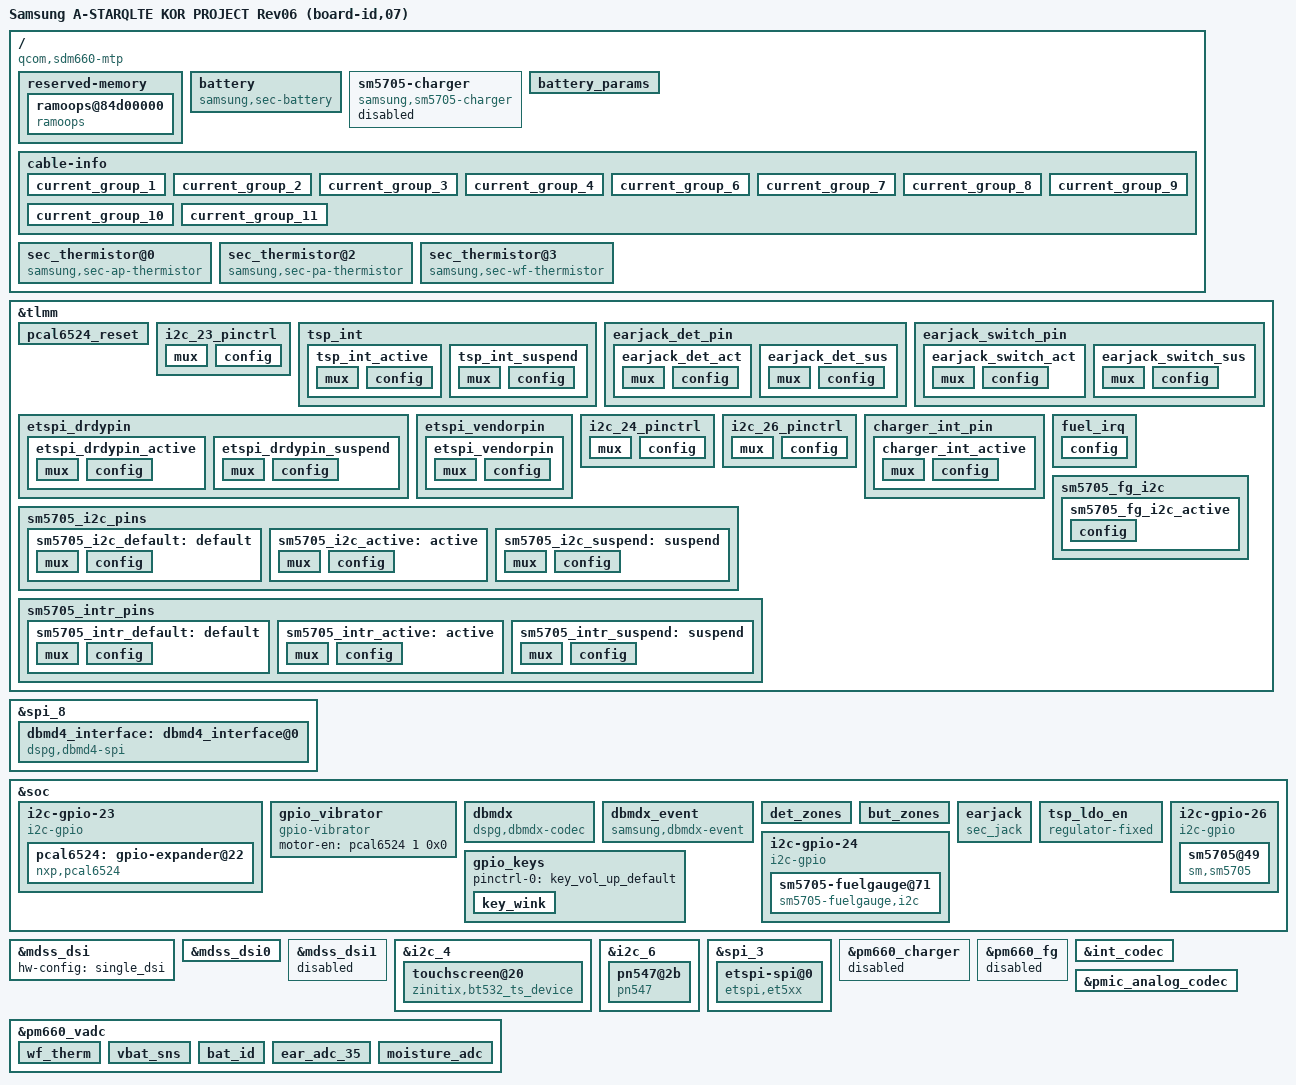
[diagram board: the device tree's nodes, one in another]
// SPDX-License-Identifier: GPL-2.0
/*
 * Samsung Galaxy A8 Star (SM-G885S, codename astarqlte, SoC SDM660).
 * Phase 1: boot essentials, volume/bixby keys, touch power and touch IC.
 */

/dts-v1/;

#include "sdm660.dtsi"
#include "sdm660-mtp.dtsi"
#include "sdm660-external-codec.dtsi"
#include "dsi-panel-s6e3fa7-ams628rf01-fhd-cmd.dtsi"
#include <dt-bindings/iio/qcom,spmi-vadc.h>

/ {
	model = "Samsung A-STARQLTE KOR PROJECT Rev06 (board-id,07)";
	compatible = "qcom,sdm660-mtp", "qcom,sdm660", "qcom,mtp";
	qcom,msm-id = <0x13d 0x0>;
	qcom,board-id = <0x8 0x7>;

	reserved-memory {
		/* base sdm660.dtsi ramoops (0x9ff00000) replaced by stock layout */
		/delete-node/ ramoops;

		ramoops@84d00000 {
			compatible = "ramoops";
			reg = <0x0 0x84d00000 0x0 0x100000>;
			record-size = <0x40000>;
			console-size = <0x40000>;
			ftrace-size = <0x40000>;
			pmsg-size = <0x40000>;
		};
	};
};

&tlmm {
	/*
	 * PCAL6524 expander reset line. Held high (out of reset) from boot,
	 * the same as the stock expander_reset_active pinctrl state.
	 */
	pcal6524_reset {
		gpio-hog;
		gpios = <33 0>;
		output-high;
		line-name = "pcal6524-reset";
	};

	i2c_23_pinctrl: i2c_23_pinctrl {
		mux {
			pins = "gpio52", "gpio51";
			function = "gpio";
		};

		config {
			pins = "gpio52", "gpio51";
			drive-strength = <2>;
			bias-disable;
		};
	};

	tsp_int {
		tsp_int_active: tsp_int_active {
			mux {
				pins = "gpio67";
				function = "gpio";
			};

			config {
				pins = "gpio67";
				drive-strength = <2>;
				bias-disable;
				input-enable;
			};
		};

		tsp_int_suspend: tsp_int_suspend {
			mux {
				pins = "gpio67";
				function = "gpio";
			};

			config {
				pins = "gpio67";
				drive-strength = <2>;
				bias-disable;
				input-enable;
			};
		};
	};
};

&tlmm {
	earjack_det_pin {
		earjack_det_act: earjack_det_act {
			mux {
				pins = "gpio43";
				function = "gpio";
			};

			config {
				pins = "gpio43";
				drive-strength = <2>;
				bias-disable;
			};
		};

		earjack_det_sus: earjack_det_sus {
			mux {
				pins = "gpio43";
				function = "gpio";
			};

			config {
				pins = "gpio43";
				drive-strength = <2>;
				bias-disable;
			};
		};
	};

	earjack_switch_pin {
		earjack_switch_act: earjack_switch_act {
			mux {
				pins = "gpio44";
				function = "gpio";
			};

			config {
				pins = "gpio44";
				drive-strength = <2>;
				bias-disable;
			};
		};

		earjack_switch_sus: earjack_switch_sus {
			mux {
				pins = "gpio44";
				function = "gpio";
			};

			config {
				pins = "gpio44";
				drive-strength = <2>;
				bias-disable;
			};
		};
	};
};

&spi_8 {
	status = "okay";

	dbmd4_interface: dbmd4_interface@0 {
		compatible = "dspg,dbmd4-spi";
		spi-max-frequency = <0xf4240>;
		read-chunk-size = <0x2000>;
		write-chunk-size = <0x40000>;
		reg = <0x0>;
		qcom,spiop-read = <0x3 0x3 0x0 0x0 0x0>;
		qcom,spiop-readseq = <0x3 0x3 0x0 0x0 0x0>;
		qcom,spiop-queryid = <0x90 0x3 0x0 0x0 0x0>;
		qcom,spiop-pprog = <0x2 0x2 0x0 0x0 0x0>;
		qcom,spiop-wenable = <0x6 0x0 0x0 0x0 0x0>;
		qcom,spiop-readst = <0x5 0x0 0x0 0x0 0x0>;
		qcom,spiop-erase = <0x20 0x2 0x0 0xa 0x1e>;
		qcom,spi-busy-mask = <0x1>;
		qcom,spi-page-size = <0x256>;
		qcom,spi-erase-size = <0x4096>;
	};
};

&soc {
	/*
	 * Stock i2c@23 (i2c-gpio, SDA = gpio52, SCL = gpio51). The PCAL6524
	 * expander and everything behind it hangs off this bus.
	 */
	i2c-gpio-23 {
		compatible = "i2c-gpio";
		gpios = <&tlmm 52 0 &tlmm 51 0>;
		i2c-gpio,delay-us = <2>;
		#address-cells = <1>;
		#size-cells = <0>;
		pinctrl-names = "default";
		pinctrl-0 = <&i2c_23_pinctrl>;

		pcal6524: gpio-expander@22 {
			compatible = "nxp,pcal6524";
			reg = <0x22>;
			gpio-controller;
			#gpio-cells = <2>;
		};
	};

	/* Motor enable is expander pin 1 (stock msm_vibrator motor-en). */
	gpio_vibrator {
		compatible = "gpio-vibrator";
		motor-en = <&pcal6524 1 0x0>;
	};

	/*
	 * dbmdx voice codec, reset is pcal6524 pin 10 as in stock r07.
	 */
	dbmdx {
		status = "okay";
		compatible = "dspg,dbmdx-codec";
		reset-gpio = <&pcal6524 10 0x0>;
		sv-gpio = <&tlmm 25 0x0>;
		wakeup-gpio = <&pm660_gpios 11 0x0>;
		auto_buffering = <0x1>;
		cmd-interface = <&dbmd4_interface>;
		feature-va;
		va-firmware-name = "dbmd4_va_fw.bin";
		va-config = <0x80000000 0x80000000 0x80000000 0x80290020 0x802210e0 0x80159494 0x801b0020 0x801a0011 0x80230001 0x80108017 0x8aab0040 0x800c7530 0x80000000 0x80000000 0x80000000>;
		va-speeds = <0x0 0x70800 0x0 0xea600 0x0 0x1e8480 0x0 0x493e00 0x0 0x2dc6c0 0x0 0x493e00>;
		va-mic-config = <0xa041 0x5044 0x28>;
		va-mic-mode = <0x0>;
		master-clk-rate = <0x8000>;
		firmware_id = <0xdbd4>;
		use_gpio_for_wakeup = <0x1>;
		wakeup_set_value = <0x0>;
		auto_detection = <0x1>;
		detection_buffer_channels = <0x0>;
		min_samples_chunk_size = <0x80>;
		pcm_streaming_mode = <0x1>;
		boot_options = <0x200>;
		send_uevent_after_buffering = <0x0>;
		detection_after_buffering = <0x0>;
		va_backlog_length = <0x70a>;
		va_backlog_length_okg = <0x3e8>;
		send_uevent_on_detection = <0x1>;
		amodel_options = <0x1b>;
		digital_mic_digital_gain = <0xa4>;
		analog_mic_analog_gain = <0x4>;
	};

	dbmdx_event {
		status = "okay";
		compatible = "samsung,dbmdx-event";
	};

	det_zones: det_zones {
		#list-det-cells = <0x4>;
	};

	but_zones: but_zones {
		#list-but-cells = <0x3>;
	};

	earjack {
		compatible = "sec_jack";
		detect-gpio = <&tlmm 43 0x0>;
		key-gpio = <&tlmm 44 0x0>;
		det-dbtime = <0x64>;
		key-dbtime = <0x1c>;
		det-zones-list = <&det_zones 0x0 0x2710 0xa 0x2>,
				 <&det_zones 0x3b6 0x2710 0xa 0x2>,
				 <&det_zones 0x3b7 0x2710 0xa 0x1>,
				 <&det_zones 0x270f 0x2710 0xa 0x1>;
		but-zones-list = <&but_zones 0xe2 0x0 0x17d>,
				 <&but_zones 0x246 0x17e 0x1a5>,
				 <&but_zones 0x73 0x1a6 0x207>,
				 <&but_zones 0x72 0x208 0x2ee>;
		use-moisture-det;
		mdet-range = <0xb1 0x4b0>;
		pinctrl-names = "earjack_gpio_active", "earjack_gpio_suspend";
		pinctrl-0 = <&earjack_det_act &earjack_switch_act>;
		pinctrl-1 = <&earjack_det_sus &earjack_switch_sus>;
	};

	tsp_ldo_en {
		compatible = "regulator-fixed";
		regulator-name = "tsp_ldo_en";
		regulator-min-microvolt = <0x1b7740>;
		regulator-max-microvolt = <0x1b7740>;
		gpio = <&pm660l_gpios 4 0x0>;
		enable-active-high;
		regulator-boot-on;
	};

	gpio_keys {
		/delete-property/ pinctrl-1;
		pinctrl-names = "default";
		pinctrl-0 = <&key_vol_up_default>;

		/delete-node/ camera_focus;
		/delete-node/ camera_snapshot;

		key_wink {
			label = "key_wink";
			gpios = <&pm660l_gpios 8 0x1>;
			linux,input-type = <1>;
			linux,code = <0x2bf>;
			gpio-key,wakeup;
			debounce-interval = <15>;
		};
	};
};

&mdss_dsi {
	hw-config = "single_dsi";
};

&mdss_dsi0 {
	qcom,dsi-pref-prim-pan = <&dsi_s6e3fa7_ams628rf01_fhd_cmd>;
	pinctrl-names = "mdss_default", "mdss_sleep";
	pinctrl-0 = <&mdss_dsi_active &mdss_te_active>;
	pinctrl-1 = <&mdss_dsi_suspend &mdss_te_suspend>;
	qcom,platform-reset-gpio = <&tlmm 53 0>;
	qcom,platform-te-gpio = <&tlmm 59 0>;
	wqhd-vddio-supply = <&pm660_l11>;
	vdda-3p3-supply = <&pm660l_l6>;
};

&mdss_dsi1 {
	status = "disabled";
};

&i2c_4 {
	status = "okay";

	touchscreen@20 {
		status = "okay";
		compatible = "zinitix,bt532_ts_device";
		reg = <0x20>;
		pinctrl-names = "on_state", "off_state";
		pinctrl-0 = <&tsp_int_active>;
		pinctrl-1 = <&tsp_int_suspend>;
		zinitix,irq_gpio = <&tlmm 67 0x0>;
		zinitix,gpio_ldo_en;
		zinitix,regulator_avdd = "tsp_ldo_en";
		zinitix,x_resolution = <0x438>;
		zinitix,y_resolution = <0x8ac>;
		zinitix,page_size = <0x80>;
		zinitix,chip_name = "ZT7548";
		zinitix,firmware_name = "tsp_zinitix/zt7548_astar.fw";
		zinitix,spay = "true";
		zinitix,aod = "true";
		zinitix,tclm_level = <0x2>;
		zinitix,afe_base = <0x800a>;
		zinitix,mis_cal_check = "true";
		clock-names = "iface_clk", "core_clk";
		clocks = <&clock_gcc GCC_BLSP1_AHB_CLK>,
			 <&clock_gcc GCC_BLSP1_QUP4_I2C_APPS_CLK>;
		zinitix,factory_item_version = <0x4>;
	};
};

&i2c_6 {
	/* The MTP NQ NFC node is not on this board; the NFC chip is a PN547. */
	/delete-node/ nq@28;

	pn547@2b {
		compatible = "pn547";
		reg = <0x2b>;
		/* Only ven and pvdd sit behind the expander; irq and firm are on tlmm. */
		pn547,irq-gpio = <&tlmm 40 0x00>;
		pn547,ven-gpio = <&pcal6524 12 0x00>;
		pn547,firm-gpio = <&tlmm 80 0x00>;
		pn547,pvdd-gpio = <&pcal6524 7 0x00>;
		pn547,nfc_pm_clk;
		clocks = <&clock_rpmcc RPM_SMD_LN_BB_CLK3_PIN>;
		clock-names = "rf_clk";
	};
};

/*
 * ET5XX fingerprint sensor (etspi) on spi_3. DRDY is tlmm gpio13 and the
 * vendor pin is gpio12, sleep and LDO enables are pcal6524 pins 15 and 6,
 * as in stock r07.
 */
&tlmm {
	etspi_drdypin {
		etspi_drdypin_active: etspi_drdypin_active {
			mux {
				pins = "gpio13";
				function = "gpio";
			};

			config {
				pins = "gpio13";
				drive-strength = <2>;
				bias-disable;
			};
		};

		etspi_drdypin_suspend: etspi_drdypin_suspend {
			mux {
				pins = "gpio13";
				function = "gpio";
			};

			config {
				pins = "gpio13";
				drive-strength = <2>;
				bias-pull-down;
			};
		};
	};

	etspi_vendorpin {
		etspi_vendorpin: etspi_vendorpin {
			mux {
				pins = "gpio12";
				function = "gpio";
			};

			config {
				pins = "gpio12";
				drive-strength = <2>;
				bias-disable;
			};
		};
	};
};

&spi_3 {
	status = "okay";

	etspi-spi@0 {
		compatible = "etspi,et5xx";
		reg = <0x0>;
		spi-max-frequency = <16000000>;
		etspi-drdyPin = <&tlmm 13 0x1>;
		etspi-sleepPin = <&pcal6524 15 0x0>;
		etspi-ldoPin = <&pcal6524 6 0x0>;
		etspi-vendorPin = <&tlmm 12 0x0>;
		etspi-min_cpufreq_limit = <0x1ec300>;
		etspi-chipid = "ET510";
		pinctrl-names = "default", "sleep", "idle";
		pinctrl-0 = <&etspi_drdypin_suspend &etspi_vendorpin>;
		pinctrl-1 = <&etspi_drdypin_suspend>;
		pinctrl-2 = <&etspi_drdypin_active>;
	};
};

/* SEC thermistors (stock sec_thermistor@0/2/3). The ADC is pm660 vadc, stock qcom,therm-vadc is replaced by io-channels. */

&tlmm {
	i2c_24_pinctrl: i2c_24_pinctrl {
		mux {
			pins = "gpio55", "gpio56";
			function = "gpio";
		};

		config {
			pins = "gpio55", "gpio56";
			drive-strength = <2>;
			bias-disable;
		};
	};

	i2c_26_pinctrl: i2c_26_pinctrl {
		mux {
			pins = "gpio72", "gpio73";
			function = "gpio";
		};

		config {
			pins = "gpio72", "gpio73";
			drive-strength = <2>;
			bias-disable;
		};
	};

	/* Not selected by any node: stock sm5705_i2c_pins, kept for later use. */
	sm5705_i2c_pins {
		sm5705_i2c_default: default {
			mux {
				pins = "gpio72", "gpio73";
				function = "gpio";
			};

			config {
				pins = "gpio72", "gpio73";
				drive-strength = <2>;
				bias-disable;
			};
		};

		sm5705_i2c_active: active {
			mux {
				pins = "gpio72", "gpio73";
				function = "gpio";
			};

			config {
				pins = "gpio72", "gpio73";
				drive-strength = <2>;
				bias-disable;
			};
		};

		sm5705_i2c_suspend: suspend {
			mux {
				pins = "gpio72", "gpio73";
				function = "gpio";
			};

			config {
				pins = "gpio72", "gpio73";
				drive-strength = <2>;
				bias-disable;
			};
		};
	};

	/* MUIC interrupt line (gpio50). Ported as pinctrl only, muic node is not ported yet. */
	sm5705_intr_pins {
		sm5705_intr_default: default {
			mux {
				pins = "gpio50";
				function = "gpio";
			};

			config {
				pins = "gpio50";
				drive-strength = <2>;
				bias-disable;
			};
		};

		sm5705_intr_active: active {
			mux {
				pins = "gpio50";
				function = "gpio";
			};

			config {
				pins = "gpio50";
				drive-strength = <2>;
				bias-disable;
			};
		};

		sm5705_intr_suspend: suspend {
			mux {
				pins = "gpio50";
				function = "gpio";
			};

			config {
				pins = "gpio50";
				drive-strength = <2>;
				bias-disable;
			};
		};
	};

	charger_int_pin {
		charger_int_active: charger_int_active {
			mux {
				pins = "gpio69";
				function = "gpio";
			};

			config {
				pins = "gpio69";
				drive-strength = <2>;
				bias-disable;
			};
		};
	};

	fuel_irq: fuel_irq {
		config {
			pins = "gpio42";
			bias-disable;
		};
	};

	sm5705_fg_i2c {
		sm5705_fg_i2c_active: sm5705_fg_i2c_active {
			config {
				pins = "gpio55", "gpio56";
				drive-strength = <2>;
				bias-disable;
				input-enable;
			};
		};
	};
};


/*
 * SM5705 owns charging and the fuel gauge on this board. The PM660 SMB2
 * charger and FG-gen3 are disabled here and off in the defconfig.
 */
&pm660_charger {
	status = "disabled";
};

&pm660_fg {
	status = "disabled";
};

/* Battery ADC channels with no node in pm660.dtsi (4.4 qpnp_get_vadc() used them). */
&pm660_vadc {
	/* stock adc_channel 0x59 (AMUX8 GPIO, WF thermistor) */
	wf_therm {
		reg = <ADC_SBUx_PU2>;
		label = "wf_therm";
		qcom,ratiometric;
		qcom,hw-settle-time = <200>;
		qcom,pre-scaling = <1 1>;
	};

	vbat_sns {
		reg = <ADC_VBAT_SNS>;
		label = "vbat_sns";
		qcom,pre-scaling = <1 1>;
	};

	bat_id {
		reg = <ADC_BAT_ID_PU2>;
		label = "bat_id";
		qcom,ratiometric;
		qcom,hw-settle-time = <200>;
		qcom,pre-scaling = <1 1>;
	};
};


&soc {
	/* Stock i2c@24 (i2c-gpio, SDA = gpio55, SCL = gpio56): fuel gauge bus. */
	i2c-gpio-24 {
		compatible = "i2c-gpio";
		gpios = <&tlmm 55 0 &tlmm 56 0>;
		i2c-gpio,delay-us = <1>;
		#address-cells = <1>;
		#size-cells = <0>;
		pinctrl-names = "default";
		pinctrl-0 = <&i2c_24_pinctrl>;

		sm5705-fuelgauge@71 {
			compatible = "sm5705-fuelgauge,i2c";
			reg = <0x71>;
			pinctrl-names = "default";
			pinctrl-0 = <&fuel_irq &sm5705_fg_i2c_active>;
			fuelgauge,fuel_int = <&tlmm 42 0x0>;
			fuelgauge,fuel_alert_soc = <1>;
			fuelgauge,capacity_max = <1000>;
			fuelgauge,capacity_max_margin = <70>;
			fuelgauge,capacity_min = <0>;
			fuelgauge,capacity_calculation_type = <31>;
			fuelgauge,type_str = "BATTERY";
			fuelgauge,model_type = <1>;
			fuelgauge,fg_log_enable = <1>;
		};
	};

	/* Stock i2c@26 (i2c-gpio, SDA = gpio72, SCL = gpio73): SM5705 MFD bus. */
	i2c-gpio-26 {
		compatible = "i2c-gpio";
		gpios = <&tlmm 72 0 &tlmm 73 0>;
		i2c-gpio,delay-us = <1>;
		#address-cells = <1>;
		#size-cells = <0>;
		pinctrl-names = "default";
		pinctrl-0 = <&i2c_26_pinctrl>;

		sm5705@49 {
			compatible = "sm,sm5705";
			reg = <0x49>;
			interrupt-parent = <&tlmm>;
			sm5705,irq-gpio = <&tlmm 69 0x0>;
			pinctrl-names = "default";
			pinctrl-0 = <&charger_int_active>;
		};
	};
};

/ {
	battery {
		status = "okay";
		compatible = "samsung,sec-battery";
		/* ADC channels used by sec_adc.c (looked up by io-channel-names) */
		io-channels = <&pm660_vadc ADC_AMUX_THM5_PU2>,
					<&pm660_vadc ADC_AMUX_THM2_PU2>,
					<&pm660_vadc ADC_VBAT_SNS>,
					<&pm660_vadc ADC_BAT_ID_PU2>;
		io-channel-names = "adc-temp", "adc-chg-temp", "adc-in-bat", "adc-bat";
		battery,vendor = "BATTERY";
		battery,charger_name = "sm5705-charger";
		battery,fuelgauge_name = "sm5705-fuelgauge";
		battery,technology = <0x2>;
		battery,batt_data_version = <0x2>;
		battery,chip_vendor = "QCOM";
		battery,temp_adc_type = <0x1>;
		battery,temp_check_type = <0x2>;
		battery,chg_temp_check = <0x1>;
		battery,wpc_temp_check = <0x0>;
		battery,thermal_source = <0x2>;
		battery,usb_thermal_source = <0x0>;
		battery,chg_thermal_source = <0x1>;
		battery,wpc_thermal_source = <0x0>;
		battery,coil_thermal_source = <0x0>;
		battery,polling_time = <0xa 0x1e 0x1e 0x1e 0xe10>;
		battery,temp_table_adc = <0x479 0x541 0x627 0x74c 0x951 0xacb 0xb89 0xd7b 0xfb8 0x1255 0x1581 0x183f 0x1ba7 0x1f0b 0x226a 0x262d 0x2a2d 0x2d9f 0x30e4 0x33de 0x3666 0x3888 0x3a4f>;
		battery,temp_table_data = <0x384 0x352 0x320 0x2ee 0x2bc 0x28a 0x258 0x226 0x1f4 0x1c2 0x190 0x15e 0x12c 0xfa 0xc8 0x96 0x64 0x32 0x0 0xffffffce 0xffffff9c 0xffffff6a 0xffffff38>;
		battery,chg_temp_table_adc = <0x449 0x52e 0x600 0x72d 0x946 0xabb 0xb9c 0xd95 0xfd7 0x1280 0x1562 0x187b 0x1be6 0x1f51 0x22ab 0x2673 0x2a68 0x2ddf 0x310c 0x3403 0x3685 0x3899 0x3a47>;
		battery,chg_temp_table_data = <0x384 0x352 0x320 0x2ee 0x2bc 0x28a 0x258 0x226 0x1f4 0x1c2 0x190 0x15e 0x12c 0xfa 0xc8 0x96 0x64 0x32 0x0 0xffffffce 0xffffff9c 0xffffff6a 0xffffff38>;
		battery,adc_check_count = <0x5>;
		battery,cable_check_type = <0x4>;
		battery,cable_source_type = <0x1>;
		battery,polling_type = <0x1>;
		battery,monitor_initial_count = <0x0>;
		battery,battery_check_type = <0x0>;
		battery,check_count = <0x0>;
		battery,check_adc_max = <0x5a0>;
		battery,check_adc_min = <0x0>;
		battery,ovp_uvlo_check_type = <0x3>;
		battery,temp_check_count = <0x1>;
		battery,temp_highlimit_threshold_event = <0x320>;
		battery,temp_highlimit_recovery_event = <0x2ee>;
		battery,temp_high_threshold_event = <0x1f4>;
		battery,temp_high_recovery_event = <0x1c2>;
		battery,temp_low_threshold_event = <0x0>;
		battery,temp_low_recovery_event = <0x32>;
		battery,temp_highlimit_threshold_normal = <0x320>;
		battery,temp_highlimit_recovery_normal = <0x2ee>;
		battery,temp_high_threshold_normal = <0x1f4>;
		battery,temp_high_recovery_normal = <0x1c2>;
		battery,temp_low_threshold_normal = <0x0>;
		battery,temp_low_recovery_normal = <0x32>;
		battery,temp_highlimit_threshold_lpm = <0x320>;
		battery,temp_highlimit_recovery_lpm = <0x2ee>;
		battery,temp_high_threshold_lpm = <0x1f4>;
		battery,temp_high_recovery_lpm = <0x1c2>;
		battery,temp_low_threshold_lpm = <0x0>;
		battery,temp_low_recovery_lpm = <0x32>;
		battery,full_check_type = <0x2>;
		battery,full_check_type_2nd = <0x2>;
		battery,full_check_count = <0x3>;
		battery,chg_gpio_full_check = <0x0>;
		battery,chg_polarity_full_check = <0x1>;
		battery,chg_high_temp = <0x1cc>;
		battery,chg_high_temp_recovery = <0x1b8>;
		battery,chg_input_limit_current = <0x3e8>;
		battery,chg_charging_limit_current = <0x4e2>;
		battery,mix_high_temp = <0x1a4>;
		battery,mix_high_chg_temp = <0x1e0>;
		battery,mix_high_temp_recovery = <0x186>;
		battery,full_condition_type = <0x9>;
		battery,full_condition_soc = <0x5d>;
		battery,full_condition_vcell = <0x109a>;
		battery,recharge_check_count = <0x1>;
		battery,recharge_condition_type = <0x4>;
		battery,recharge_condition_soc = <0x62>;
		battery,recharge_condition_vcell = <0x10b8>;
		battery,standard_curr = <0x960>;
		battery,expired_time = <0x2a30>;
		battery,recharging_expired_time = <0x1518>;
		battery,charging_reset_time = <0x0>;
		battery,chg_float_voltage = <0x10fe>;
		battery,pre_afc_work_delay = <0x7d0>;
		battery,pre_afc_input_current = <0x1f4>;
		battery,swelling_high_temp_block = <0x19a>;
		battery,swelling_high_temp_recov = <0x186>;
		battery,swelling_low_temp_block_1st = <0x96>;
		battery,swelling_low_temp_recov_1st = <0xc8>;
		battery,swelling_low_temp_block_2nd = <0x32>;
		battery,swelling_low_temp_recov_2nd = <0x64>;
		battery,swelling_low_temp_current = <0x352>;
		battery,swelling_low_temp_topoff = <0xb9>;
		battery,swelling_high_temp_current = <0x514>;
		battery,swelling_high_temp_topoff = <0xb9>;
		battery,swelling_drop_float_voltage = <0x1036>;
		battery,swelling_high_rechg_voltage = <0xfa0>;
		battery,swelling_low_rechg_voltage = <0xfa0>;
		battery,siop_event_check_type = <0x1>;
		battery,siop_call_cv_current = <0x14a>;
		battery,siop_call_cc_current = <0x14a>;
		battery,siop_input_limit_current = <0x4b0>;
		battery,siop_charging_limit_current = <0x3e8>;
		battery,siop_hv_input_limit_current = <0x1f4>;
		battery,siop_hv_charging_limit_current = <0x3e8>;
		battery,age_data = <0x0 0x10fe 0x10b8 0x109a 0x5d 0xc8 0x10ea 0x10a4 0x1081 0x5c 0xfa 0x10d6 0x1090 0x1074 0x5b 0x12c 0x10c2 0x107c 0x105b 0x5a 0x3e8 0x1090 0x104a 0x1029 0x59>;
		battery,pd_charging_charge_power = <0x3a98>;
		battery,max_input_voltage = <0x2328>;
		battery,max_input_current = <0xbb8>;
		battery,max_charging_current = <0x960>;
		battery,enable_sysovlo_irq;
		battery,battery_full_capacity = <0xe74>;
		battery,cisd_qh_current_low_thr = <0xbe>;
		battery,cisd_qh_current_high_thr = <0xd2>;
		battery,cisd_qh_vfsoc_thr = <0x186a0>;
		battery,cisd_max_voltage_thr = <0x1388>;
		battery,cisd_alg_index = <0x7>;
		battery,full_chg_current_margin = <0x0>;
	};

	sm5705-charger {
		status = "disable";
		compatible = "samsung,sm5705-charger";
		battery,chg_gpio_en = <&tlmm 63 0x0>;
		battery,chg_polarity_en = <0x0>;
		battery,chg_gpio_status = <0x0>;
		battery,chg_polarity_status = <0x0>;
	};

	battery_params {
		battery,id = <0x0>;
		battery0,battery_type = <0x10cc>;
		battery0,battery_table0 = <0x1400 0x1b33 0x1cda 0x1d6c 0x1d94 0x1dd8 0x1e26 0x1e8a 0x1ed0 0x1f89 0x1fbe 0x2012 0x2071 0x20f1 0x225f 0x2400>;
		battery0,battery_table1 = <0x0 0x34 0xed 0x182 0x392 0x50d 0x804 0xd37 0xf6c 0x1263 0x13de 0x1559 0x1613 0x1850 0x1d0c 0x1d13>;
		battery0,rce_value = <0x4e1 0x3e6 0x1d7>;
		battery0,rs_value = <0x51 0x147 0x146 0x3800 0x7a>;
		battery0,misc = <0x60>;
		battery0,topoff_soc = <0x0 0x3 0x172>;
		battery0,vit_period = <0x3506>;
		battery0,dtcd_value = <0x1>;
		battery0,volt_cal = <0x8000>;
		battery0,curr_offset = <0x1 0x0>;
		battery0,p_curr_cal = <0x88>;
		battery0,n_curr_cal = <0x84>;
		battery0,mix_value = <0x403 0x4>;
		battery0,temp_std = <0x19>;
		battery0,temp_cal = <0x1 0x6 0x1 0xb 0xffffffff 0x1 0x6 0x1 0x9 0x1>;
		battery0,ext_temp_cal = <0x1 0x3 0x0 0x3 0x1 0x1 0x2 0x3 0x2 0x3>;
		battery0,temp_volcal = <0x1 0x2d 0x1>;
		battery0,temp_offset = <0x1 0xb 0x1 0x1 0x8 0xffffffff>;
		battery0,cycle_cfg = <0x7 0x1 0x3>;
		battery0,curr_lcal = <0x0 0x8888 0x8888 0x8888>;
		battery0,tem_poff = <0xd34 0x32 0xcf8 0x32>;
		battery0,v_offset_cancel = <0x1 0x0 0x64 0x2>;
		battery0,v_alarm = <0xbb8>;
		battery0,v_max_table = <0x225f 0x2239 0x2213 0x21ed 0x218d>;
		battery0,q_max_table = <0x1d0c 0x1c87 0x1c03 0x1b7e 0x1a33>;
		battery0,data_ver = <0x3>;
	};

	cable-info {
		default_input_current = <0x708>;
		default_charging_current = <0x834>;
		full_check_current_1st = <0x172>;
		full_check_current_2nd = <0xb9>;

		current_group_1 {
			cable_number = <0x1 0x2 0x4 0x13 0x15 0x16 0x17 0x1e>;
			input_current = <0x1f4>;
			charging_current = <0x1f4>;
		};

		current_group_2 {
			cable_number = <0x19 0x1f>;
			input_current = <0x3e8>;
			charging_current = <0x3e8>;
		};

		current_group_3 {
			cable_number = <0x5 0x20>;
			input_current = <0x5dc>;
			charging_current = <0x5dc>;
		};

		current_group_4 {
			cable_number = <0x6 0x7 0x8 0x9 0x11 0x12>;
			input_current = <0x640>;
			charging_current = <0x960>;
		};

		current_group_6 {
			cable_number = <0xa 0xc 0xe 0xf 0x1b>;
			input_current = <0x384>;
			charging_current = <0x4e2>;
		};

		current_group_7 {
			cable_number = <0xd>;
			input_current = <0x2bc>;
			charging_current = <0x4e2>;
		};

		current_group_8 {
			cable_number = <0x18>;
			input_current = <0x3e8>;
			charging_current = <0x1c2>;
		};

		current_group_9 {
			cable_number = <0x1a>;
			input_current = <0x708>;
			charging_current = <0x708>;
		};

		current_group_10 {
			cable_number = <0xb 0x10 0x1c>;
			input_current = <0x28a>;
			charging_current = <0x4e2>;
		};

		current_group_11 {
			cable_number = <0x1d>;
			input_current = <0x1f4>;
			charging_current = <0x4e2>;
		};
	};
		sec_thermistor@0 {
			compatible = "samsung,sec-ap-thermistor";
			io-channels = <&pm660_vadc ADC_AMUX_THM1_PU2>;
			io-channel-names = "therm";
			adc_array = <0x415 0x4dd 0x5c3 0x6e8 0x8f5 0xa68 0xb16 0xb7b 0xbe0 0xc44 0xca9 0xd0e 0xd83 0xdf8 0xe6d 0xee2 0xf57 0xfda 0x105d 0x10e0 0x1163 0x11e6 0x127a 0x130e 0x13a2 0x1436 0x14ca 0x1567 0x1605 0x16a2 0x1740 0x17dd 0x1888 0x1932 0x19dd 0x1a87 0x1b32 0x1be0 0x1c8e 0x1d3c 0x1dea 0x1e98 0x1f40 0x1fe8 0x2090 0x2138 0x21e0 0x22a0 0x2360 0x2421 0x24e1 0x25a1 0x2667 0x272d 0x27f3 0x28b9 0x297f 0x2a30 0x2ae1 0x2b92 0x2c43 0x2cf4 0x2d89 0x2e1e 0x2eb4 0x2f49 0x2fde 0x3074 0x310a 0x319f 0x3235 0x32cb 0x3352 0x33d9 0x3461 0x34e8 0x356f 0x35d8 0x3641 0x36ab 0x3714 0x377d 0x37da 0x3837 0x3893 0x38f0 0x394d>;
			temp_array = <0x384 0x352 0x320 0x2ee 0x2bc 0x28a 0x258 0x24e 0x244 0x23a 0x230 0x226 0x21c 0x212 0x208 0x1fe 0x1f4 0x1ea 0x1e0 0x1d6 0x1cc 0x1c2 0x1b8 0x1ae 0x1a4 0x19a 0x190 0x186 0x17c 0x172 0x168 0x15e 0x154 0x14a 0x140 0x136 0x12c 0x122 0x118 0x10e 0x104 0xfa 0xf0 0xe6 0xdc 0xd2 0xc8 0xbe 0xb4 0xaa 0xa0 0x96 0x8c 0x82 0x78 0x6e 0x64 0x5a 0x50 0x46 0x3c 0x32 0x28 0x1e 0x14 0xa 0x0 0xfffffff6 0xffffffec 0xffffffe2 0xffffffd8 0xffffffce 0xffffffc4 0xffffffba 0xffffffb0 0xffffffa6 0xffffff9c 0xffffff92 0xffffff88 0xffffff7e 0xffffff74 0xffffff6a 0xffffff60 0xffffff56 0xffffff4c 0xffffff42 0xffffff38>;
		};
		sec_thermistor@2 {
			compatible = "samsung,sec-pa-thermistor";
			io-channels = <&pm660_vadc ADC_AMUX_THM3_PU2>;
			io-channel-names = "therm";
			adc_array = <0x4e9 0x56b 0x628 0x739 0x8a1 0xa18 0xbac 0xbe3 0xc1a 0xc51 0xcbb 0xd26 0xd90 0xdfe 0xe6b 0xed9 0xf5a 0xfdb 0x105c 0x10d4 0x114c 0x11c4 0x1252 0x12df 0x136d 0x1403 0x1499 0x1530 0x15d2 0x1675 0x1717 0x17bb 0x185f 0x1904 0x19cb 0x1a92 0x1b59 0x1c2d 0x1ce1 0x1d95 0x1e49 0x1f05 0x1ff7 0x20ab 0x215f 0x2213 0x22d7 0x23b7 0x246c 0x2520 0x25d4 0x2693 0x2762 0x2816 0x28ca 0x297e 0x2a39 0x2aed 0x2ba1 0x2c55 0x2d09 0x2dbe 0x2e61 0x2f00 0x2f9f 0x303e 0x30dd 0x3166 0x31ef 0x3278 0x3301 0x338a 0x340e 0x3491 0x3514 0x3597 0x361a 0x3696 0x3712 0x378e 0x380a 0x3886 0x38a6 0x3902 0x395d 0x39f4 0x3a4d>;
			temp_array = <0x384 0x352 0x320 0x2ee 0x2bc 0x28a 0x258 0x24e 0x244 0x23a 0x230 0x226 0x21c 0x212 0x208 0x1fe 0x1f4 0x1ea 0x1e0 0x1d6 0x1cc 0x1c2 0x1b8 0x1ae 0x1a4 0x19a 0x190 0x186 0x17c 0x172 0x168 0x15e 0x154 0x14a 0x140 0x136 0x12c 0x122 0x118 0x10e 0x104 0xfa 0xf0 0xe6 0xdc 0xd2 0xc8 0xbe 0xb4 0xaa 0xa0 0x96 0x8c 0x82 0x78 0x6e 0x64 0x5a 0x50 0x46 0x3c 0x32 0x28 0x1e 0x14 0xa 0x0 0xfffffff6 0xffffffec 0xffffffe2 0xffffffd8 0xffffffce 0xffffffc4 0xffffffba 0xffffffb0 0xffffffa6 0xffffff9c 0xffffff92 0xffffff88 0xffffff7e 0xffffff74 0xffffff6a 0xffffff60 0xffffff56 0xffffff4c 0xffffff42 0xffffff38>;
		};
		sec_thermistor@3 {
			compatible = "samsung,sec-wf-thermistor";
			io-channels = <&pm660_vadc ADC_SBUx_PU2>;
			io-channel-names = "therm";
			adc_array = <0x4e9 0x56b 0x628 0x6f0 0x809 0xa0a 0xbcf 0xc27 0xc80 0xce8 0xd50 0xdb8 0xe29 0xe99 0xf0a 0xf85 0xfff 0x107a 0x10fd 0x1180 0x1203 0x128d 0x1316 0x13a0 0x142e 0x14bb 0x1549 0x15fc 0x16af 0x1763 0x1816 0x18c9 0x197b 0x1a2c 0x1ade 0x1b90 0x1c42 0x1cfc 0x1db6 0x1e70 0x1f2a 0x1fe4 0x20a1 0x215f 0x221c 0x22da 0x2398 0x2456 0x2515 0x25d4 0x2693 0x2752 0x280a 0x28c1 0x2979 0x2a31 0x2ae9 0x2b8b 0x2c2d 0x2ccf 0x2d71 0x2e13 0x2eba 0x2f62 0x3009 0x30b1 0x3158 0x31e5 0x3272 0x32fe 0x338b 0x3418 0x349a 0x351c 0x31b6 0x3620 0x36a2 0x370b 0x3775 0x37de 0x3847 0x38b1 0x3904 0x3958 0x39ac 0x3a00 0x3a54>;
			temp_array = <0x384 0x352 0x320 0x2ee 0x2bc 0x28a 0x258 0x24e 0x244 0x23a 0x230 0x226 0x21c 0x212 0x208 0x1fe 0x1f4 0x1ea 0x1e0 0x1d6 0x1cc 0x1c2 0x1b8 0x1ae 0x1a4 0x19a 0x190 0x186 0x17c 0x172 0x168 0x15e 0x154 0x14a 0x140 0x136 0x12c 0x122 0x118 0x10e 0x104 0xfa 0xf0 0xe6 0xdc 0xd2 0xc8 0xbe 0xb4 0xaa 0xa0 0x96 0x8c 0x82 0x78 0x6e 0x64 0x5a 0x50 0x46 0x3c 0x32 0x28 0x1e 0x14 0xa 0x0 0xfffffff6 0xffffffec 0xffffffe2 0xffffffd8 0xffffffce 0xffffffc4 0xffffffba 0xffffffb0 0xffffffa6 0xffffff9c 0xffffff92 0xffffff88 0xffffff7e 0xffffff74 0xffffff6a 0xffffff60 0xffffff56 0xffffff4c 0xffffff42 0xffffff38>;
		};
};

/*
 * Stock r07 nodes not yet ported (no driver or DT binding in this tree yet):
 * not yet: sm5705 muic (muic-sm5705@25), sm5705 fled, sm5705 rgb, sm5705 usbldo,
 * not yet: mdss_disp_det pinctrl (gpio 45/49), dfps_data_mem,
 * not yet: s2mm005 usb-pd, sec_ts (second touch IC on i2c_4),
 * not yet: q6audio-adaptation (SEC_SND_ADAPTATION),
 * not yet: camera flash, tdmb, usb-temp adc channel (gpio5 has no 4.19 ADC5 entry),
 * not yet: usb-notifier, i2c-gpio buses 21/25/27, ss_plog, sec_debug/tima regions,
 * not yet: /chosen (stdout-path, bootargs), bt_wcn3990, input_booster.
 */

/*
 * Samsung 3.5 mm earjack (sec_jack) ADC inputs. The ear and moisture
 * sense lines sit on PM660 VADC hw channels GPIO6 (0x17) and GPIO2 (0x13),
 * the same channels stock r07 used (amux_channel / moisture-channel).
 * The machine driver resolves them by io-channel-names.
 */
&pm660_vadc {
	ear_adc_35 {
		reg = <ADC_GPIO6>;
		label = "ear_adc_35";
		qcom,pre-scaling = <1 1>;
	};

	moisture_adc {
		reg = <ADC_GPIO2>;
		label = "moisture_adc";
		qcom,pre-scaling = <1 1>;
	};
};

&int_codec {
	status = "okay";
	io-channels = <&pm660_vadc ADC_GPIO6>, <&pm660_vadc ADC_GPIO2>;
	io-channel-names = "earjack-read", "moisture-read";
};

&pmic_analog_codec {
	status = "okay";
};
